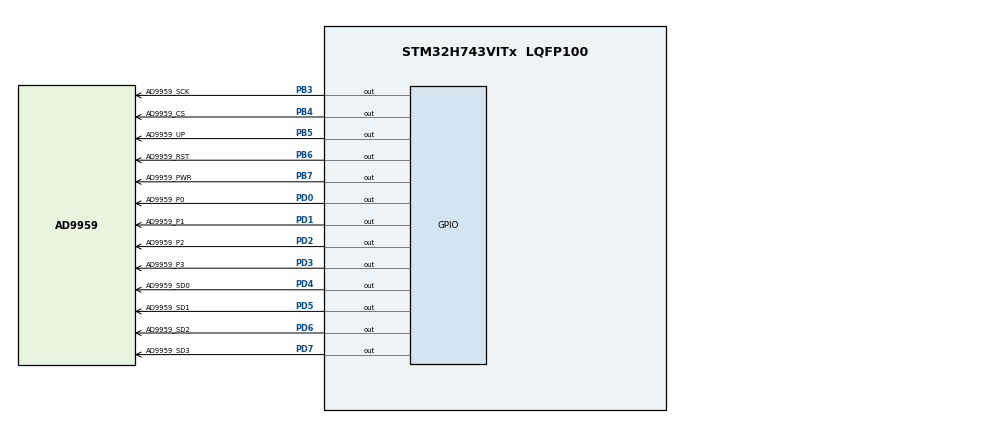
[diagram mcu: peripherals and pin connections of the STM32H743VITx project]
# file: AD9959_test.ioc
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Mcu.Family=STM32H7
Mcu.Name=STM32H743VITx
Mcu.Package=LQFP100
NVIC.PriorityGroup=NVIC_PRIORITYGROUP_4
PA13\ (JTMS/SWDIO).Mode=Serial_Wire
PA13\ (JTMS/SWDIO).Signal=DEBUG_JTMS-SWDIO
PA14\ (JTCK/SWCLK).Mode=Serial_Wire
PA14\ (JTCK/SWCLK).Signal=DEBUG_JTCK-SWCLK
PB3\ (JTDO/TRACESWO).GPIO_Label=AD9959_SCK
PB3\ (JTDO/TRACESWO).GPIO_Speed=GPIO_SPEED_FREQ_VERY_HIGH
PB3\ (JTDO/TRACESWO).Signal=GPIO_Output
PB4\ (NJTRST).GPIO_Label=AD9959_CS
PB4\ (NJTRST).GPIO_Speed=GPIO_SPEED_FREQ_VERY_HIGH
PB4\ (NJTRST).PinState=GPIO_PIN_SET
PB4\ (NJTRST).Signal=GPIO_Output
PB5.GPIO_Label=AD9959_UP
PB5.GPIO_Speed=GPIO_SPEED_FREQ_VERY_HIGH
PB5.Signal=GPIO_Output
PB6.GPIO_FM6=__NULL
PB6.GPIO_Label=AD9959_RST
PB6.GPIO_Speed=GPIO_SPEED_FREQ_VERY_HIGH
PB6.Signal=GPIO_Output
PB7.GPIO_FM7=__NULL
PB7.GPIO_Label=AD9959_PWR
PB7.GPIO_Speed=GPIO_SPEED_FREQ_VERY_HIGH
PB7.Signal=GPIO_Output
PD0.GPIO_Label=AD9959_P0
PD0.GPIO_Speed=GPIO_SPEED_FREQ_VERY_HIGH
PD0.Signal=GPIO_Output
PD1.GPIO_Label=AD9959_P1
PD1.GPIO_Speed=GPIO_SPEED_FREQ_VERY_HIGH
PD1.Signal=GPIO_Output
PD2.GPIO_Label=AD9959_P2
PD2.GPIO_Speed=GPIO_SPEED_FREQ_VERY_HIGH
PD2.Signal=GPIO_Output
PD3.GPIO_Label=AD9959_P3
PD3.GPIO_Speed=GPIO_SPEED_FREQ_VERY_HIGH
PD3.Signal=GPIO_Output
PD4.GPIO_Label=AD9959_SD0
PD4.GPIO_Speed=GPIO_SPEED_FREQ_VERY_HIGH
PD4.Signal=GPIO_Output
PD5.GPIO_Label=AD9959_SD1
PD5.GPIO_Speed=GPIO_SPEED_FREQ_VERY_HIGH
PD5.Signal=GPIO_Output
PD6.GPIO_Label=AD9959_SD2
PD6.GPIO_Speed=GPIO_SPEED_FREQ_VERY_HIGH
PD6.Signal=GPIO_Output
PD7.GPIO_Label=AD9959_SD3
PD7.GPIO_Speed=GPIO_SPEED_FREQ_VERY_HIGH
PD7.Signal=GPIO_Output
PH0-OSC_IN\ (PH0).Mode=HSE-External-Oscillator
PH0-OSC_IN\ (PH0).Signal=RCC_OSC_IN
PH1-OSC_OUT\ (PH1).Mode=HSE-External-Oscillator
PH1-OSC_OUT\ (PH1).Signal=RCC_OSC_OUT
ProjectManager.HeapSize=0x200
ProjectManager.StackSize=0x400
ProjectManager.TargetToolchain=MDK-ARM V5.32
RCC.ADCFreq_Value=180000000
RCC.APB1Freq_Value=120000000
RCC.APB2Freq_Value=120000000
RCC.APB3Freq_Value=120000000
RCC.APB4Freq_Value=120000000
RCC.CortexFreq_Value=480000000
RCC.D1PPRE=RCC_APB3_DIV2
RCC.D2PPRE1=RCC_APB1_DIV2
RCC.D2PPRE2=RCC_APB2_DIV2
RCC.D3PPRE=RCC_APB4_DIV2
RCC.DIVM1=5
RCC.DIVM2=25
RCC.DIVN1=192
RCC.DIVN2=360
RCC.HCLKFreq_Value=240000000
RCC.HPRE=RCC_HCLK_DIV2
RCC.PLLSourceVirtual=RCC_PLLSOURCE_HSE
RCC.SYSCLKFreq_VALUE=480000000
RCC.SYSCLKSource=RCC_SYSCLKSOURCE_PLLCLK
RCC.USBFreq_Value=480000000
TIM7.Prescaler=240
VP_TIM7_VS_ClockSourceINT.Mode=Enable_Timer
board=custom

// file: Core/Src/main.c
/* USER CODE BEGIN Header */
/**
  ******************************************************************************
  * @file           : main.c
  * @brief          : Main program body
  ******************************************************************************
  * @attention
  *
  * Copyright (c) 2022 STMicroelectronics.
  * All rights reserved.
  *
  * This software is licensed under terms that can be found in the LICENSE file
  * in the root directory of this software component.
  * If no LICENSE file comes with this software, it is provided AS-IS.
  *
  ******************************************************************************
  */
/* USER CODE END Header */
#include "main.h"
#include "tim.h"
#include "gpio.h"

void SystemClock_Config(void);

int main(void)
{

  /* MCU Configuration--------------------------------------------------------*/

  /* Reset of all peripherals, Initializes the Flash interface and the Systick. */
  HAL_Init();

  /* Configure the system clock */
  SystemClock_Config();

  /* Initialize all configured peripherals */
//  MX_GPIO_Init();
  MX_TIM7_Init();
  /* USER CODE BEGIN 2 */

	Init_AD9959();

//	for(int fail = 0;fail <5;fail++)
//	Write_frequence(0,200000);

//	Write_frequence(0,10000000);
//
//	Write_Amplitude(1,)
  /* USER CODE END 2 */

  /* Infinite loop */
  while (1)
  {
//		Delay_Ms(300);
  }
}

void SystemClock_Config(void)
{
  RCC_OscInitTypeDef RCC_OscInitStruct = {0};
  RCC_ClkInitTypeDef RCC_ClkInitStruct = {0};

  /** Supply configuration update enable
  */
  HAL_PWREx_ConfigSupply(PWR_LDO_SUPPLY);

  /** Configure the main internal regulator output voltage
  */
  __HAL_PWR_VOLTAGESCALING_CONFIG(PWR_REGULATOR_VOLTAGE_SCALE1);

  while(!__HAL_PWR_GET_FLAG(PWR_FLAG_VOSRDY)) {}

  __HAL_RCC_SYSCFG_CLK_ENABLE();
  __HAL_PWR_VOLTAGESCALING_CONFIG(PWR_REGULATOR_VOLTAGE_SCALE0);

  while(!__HAL_PWR_GET_FLAG(PWR_FLAG_VOSRDY)) {}

  /** Initializes the RCC Oscillators according to the specified parameters
  * in the RCC_OscInitTypeDef structure.
  */
  RCC_OscInitStruct.OscillatorType = RCC_OSCILLATORTYPE_HSE;
  RCC_OscInitStruct.HSEState = RCC_HSE_ON;
  RCC_OscInitStruct.PLL.PLLState = RCC_PLL_ON;
  RCC_OscInitStruct.PLL.PLLSource = RCC_PLLSOURCE_HSE;
  RCC_OscInitStruct.PLL.PLLM = 5;
  RCC_OscInitStruct.PLL.PLLN = 192;
  RCC_OscInitStruct.PLL.PLLP = 2;
  RCC_OscInitStruct.PLL.PLLQ = 2;
  RCC_OscInitStruct.PLL.PLLR = 2;
  RCC_OscInitStruct.PLL.PLLRGE = RCC_PLL1VCIRANGE_2;
  RCC_OscInitStruct.PLL.PLLVCOSEL = RCC_PLL1VCOWIDE;
  RCC_OscInitStruct.PLL.PLLFRACN = 0;
  if (HAL_RCC_OscConfig(&RCC_OscInitStruct) != HAL_OK)
  {
    Error_Handler();
  }

  /** Initializes the CPU, AHB and APB buses clocks
  */
  RCC_ClkInitStruct.ClockType = RCC_CLOCKTYPE_HCLK|RCC_CLOCKTYPE_SYSCLK
                              |RCC_CLOCKTYPE_PCLK1|RCC_CLOCKTYPE_PCLK2
                              |RCC_CLOCKTYPE_D3PCLK1|RCC_CLOCKTYPE_D1PCLK1;
  RCC_ClkInitStruct.SYSCLKSource = RCC_SYSCLKSOURCE_PLLCLK;
  RCC_ClkInitStruct.SYSCLKDivider = RCC_SYSCLK_DIV1;
  RCC_ClkInitStruct.AHBCLKDivider = RCC_HCLK_DIV2;
  RCC_ClkInitStruct.APB3CLKDivider = RCC_APB3_DIV2;
  RCC_ClkInitStruct.APB1CLKDivider = RCC_APB1_DIV2;
  RCC_ClkInitStruct.APB2CLKDivider = RCC_APB2_DIV2;
  RCC_ClkInitStruct.APB4CLKDivider = RCC_APB4_DIV2;

  if (HAL_RCC_ClockConfig(&RCC_ClkInitStruct, FLASH_LATENCY_4) != HAL_OK)
  {
    Error_Handler();
  }
}

void Error_Handler(void)
{
  __disable_irq();
  while (1)
  {
  }
}
